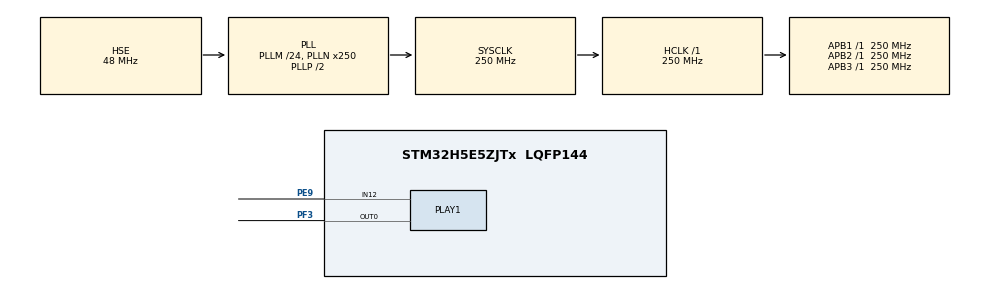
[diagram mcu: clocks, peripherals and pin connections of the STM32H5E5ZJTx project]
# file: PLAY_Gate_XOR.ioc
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CORTEX_M33_NS.userName=CORTEX_M33
Mcu.Family=STM32H5
Mcu.Name=STM32H5E5ZJTx
Mcu.Package=LQFP144
NVIC.PriorityGroup=NVIC_PRIORITYGROUP_4
PE9.GPIO_PuPd=GPIO_PULLDOWN
PE9.GPIO_Speed=GPIO_SPEED_FREQ_HIGH
PE9.Mode=PLAY1_IN12
PE9.Signal=PLAY1_IN12
PF3.GPIO_Speed=GPIO_SPEED_FREQ_HIGH
PF3.Mode=PLAY1_OUT0
PF3.Signal=PLAY1_OUT0
PH0-OSC_IN(PH0).Mode=HSE-External-Oscillator
PH0-OSC_IN(PH0).Signal=RCC_OSC_IN
PH1-OSC_OUT(PH1).Mode=HSE-External-Oscillator
PH1-OSC_OUT(PH1).Signal=RCC_OSC_OUT
PLAY1.Channel-PLAY1_IN12=PLAY_CHANNEL_12
PLAY1.InputPulseWidth12=100
PLAY1.InputSignal12=HAL_PLAY1_IN_IN12_MUX12
PLAY1.L0Input0=HAL_PLAY_LUT_INPUT_FILTER12
PLAY1.L0Input1=HAL_PLAY_LUT_INPUT_SWTRIG0
PLAY1.L0InputType0=InputSignal
PLAY1.L0LUT=0x6666
PLAY1.L1Input0=HAL_PLAY_LUT_INPUT_LUT11_OUT_REGISTERED
PLAY1.L1InputType0=OutputRegisteredSignal
PLAY1.L1InputType1=SWIN
PLAY1.LUT0InputUsage0=enable
PLAY1.LUT0InputUsage1=enable
PLAY1.LUT1InputUsage0=disable
PLAY1.LUT1InputUsage1=disable
PLAY1.OutputSignal0=HAL_PLAY_LUT0_OUT_DIRECT
ProjectManager.HeapSize=0x200
ProjectManager.StackSize=0x400
ProjectManager.TargetToolchain=EWARM V9.20
RCC.ADCFreq_Value=250000000
RCC.AHBFreq_Value=250000000
RCC.APB1Freq_Value=250000000
RCC.APB1TimFreq_Value=250000000
RCC.APB2Freq_Value=250000000
RCC.APB2TimFreq_Value=250000000
RCC.APB3Freq_Value=250000000
RCC.CSI_VALUE=4000000
RCC.CortexFreq_Value=250000000
RCC.EPOD_VALUE=48000000
RCC.HCLKFreq_Value=250000000
RCC.HSE_VALUE=48000000
RCC.HSI48_VALUE=48000000
RCC.HSI_VALUE=64000000
RCC.LSE_VALUE=32768
RCC.LSIRC_VALUE=32000
RCC.PLAY1CLockSelection=RCC_PLAY1CLKSOURCE_PLL2P
RCC.PLL2M=2
RCC.PLL2N=8
RCC.PLL2Source=RCC_PLL2_SOURCE_HSI
RCC.PLLM=24
RCC.PLLN=250
RCC.PLLSourceVirtual=RCC_PLL1_SOURCE_HSE
RCC.SYSCLKFreq_VALUE=250000000
RCC.SYSCLKSource=RCC_SYSCLKSOURCE_PLLCLK
RCC.USBFreq_Value=258000000
RCC.VCOOutputFreq_Value=500000000
VP_CORTEX_M33_NS_VS_Hclk.Mode=Hclk_Mode
VP_ICACHE_VS_ICACHE.Mode=DefaultMode
VP_PLAY1_VS_PLA.Mode=PLAY_Activate
VP_PWR_VS_LPOM.Mode=PowerOptimisation
VP_PWR_VS_SECSignals.Mode=Security/Privilege
board=custom

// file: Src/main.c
/* USER CODE BEGIN Header */
/**
  ******************************************************************************
  * @file           : main.c
  * @brief          : Main program body
  ******************************************************************************
  * @attention
  *
  * Copyright (c) 2025 STMicroelectronics.
  * All rights reserved.
  *
  * This software is licensed under terms that can be found in the LICENSE file
  * in the root directory of this software component.
  * If no LICENSE file comes with this software, it is provided AS-IS.
  *
  ******************************************************************************
  */
/* USER CODE END Header */
#include "main.h"

#define CONFIGURED_INPUT_NBR   1U
#define CONFIGURED_LUT_NBR     1U
#define CONFIGURED_OUTPUT_NBR  1U

HAL_PLAY_HandleTypeDef hplay1;

void SystemClock_Config(void);
static void MX_GPIO_Init(void);
static void MX_ICACHE_Init(void);
static void MX_PLAY1_Init(void);

int main(void)
{

  /* USER CODE BEGIN 1 */
  HAL_PLAY_EdgeTriggerConfTypeDef edge_trigger_config;

  /* USER CODE END 1 */

  /* MCU Configuration--------------------------------------------------------*/

  /* Reset of all peripherals, Initializes the Flash interface and the Systick. */
  HAL_Init();

  /* Configure the system clock */
  SystemClock_Config();

  /* Initialize all configured peripherals */
  MX_GPIO_Init();
  MX_ICACHE_Init();
  MX_PLAY1_Init();
  /* USER CODE BEGIN 2 */
  BSP_LED_Init(LED_RED);

  /* In this example, edge triggers are not used */
  edge_trigger_config.lut_out_falling_mask = 0U;
  edge_trigger_config.lut_out_rising_mask = 0U;

  /* Start PLAY module */
  if (HAL_PLAY_Start(&hplay1, &edge_trigger_config) != HAL_OK)
  {
    Error_Handler();
  }

  /* USER CODE END 2 */

  /* Infinite loop */
  /* USER CODE BEGIN WHILE */
  while (1)
  {
    /* Toggle the second input with a software trigger */
    if (HAL_PLAY_ToggleSWTrigger(&hplay1, HAL_PLAY_SWTRIG0, 100U) != HAL_OK)
    {
      Error_Handler();
    }

    HAL_Delay(1000);

    /* USER CODE END WHILE */

  }
}

void SystemClock_Config(void)
{
  RCC_OscInitTypeDef RCC_OscInitStruct = {0};
  RCC_ClkInitTypeDef RCC_ClkInitStruct = {0};

  /** Configure the main internal regulator output voltage
  */
  __HAL_PWR_VOLTAGESCALING_CONFIG(PWR_REGULATOR_VOLTAGE_SCALE0);

  while(!__HAL_PWR_GET_FLAG(PWR_FLAG_VOSRDY)) {}

  /** Initializes the RCC Oscillators according to the specified parameters
  * in the RCC_OscInitTypeDef structure.
  */
  RCC_OscInitStruct.OscillatorType = RCC_OSCILLATORTYPE_HSI|RCC_OSCILLATORTYPE_HSE;
  RCC_OscInitStruct.HSEState = RCC_HSE_ON;
  RCC_OscInitStruct.HSIState = RCC_HSI_ON;
  RCC_OscInitStruct.HSIDiv = RCC_HSI_DIV2;
  RCC_OscInitStruct.HSICalibrationValue = RCC_HSICALIBRATION_DEFAULT;
  RCC_OscInitStruct.PLL.PLLState = RCC_PLL_ON;
  RCC_OscInitStruct.PLL.PLLSource = RCC_PLL1_SOURCE_HSE;
  RCC_OscInitStruct.PLL.PLLM = 24;
  RCC_OscInitStruct.PLL.PLLN = 250;
  RCC_OscInitStruct.PLL.PLLP = 2;
  RCC_OscInitStruct.PLL.PLLQ = 2;
  RCC_OscInitStruct.PLL.PLLR = 2;
  RCC_OscInitStruct.PLL.PLLRGE = RCC_PLL1_VCIRANGE_1;
  RCC_OscInitStruct.PLL.PLLVCOSEL = RCC_PLL1_VCORANGE_WIDE;
  RCC_OscInitStruct.PLL.PLLFRACN = 0;
  if (HAL_RCC_OscConfig(&RCC_OscInitStruct) != HAL_OK)
  {
    Error_Handler();
  }

  /** Initializes the CPU, AHB and APB buses clocks
  */
  RCC_ClkInitStruct.ClockType = RCC_CLOCKTYPE_HCLK|RCC_CLOCKTYPE_SYSCLK
                              |RCC_CLOCKTYPE_PCLK1|RCC_CLOCKTYPE_PCLK2
                              |RCC_CLOCKTYPE_PCLK3;
  RCC_ClkInitStruct.SYSCLKSource = RCC_SYSCLKSOURCE_PLLCLK;
  RCC_ClkInitStruct.AHBCLKDivider = RCC_SYSCLK_DIV1;
  RCC_ClkInitStruct.APB1CLKDivider = RCC_HCLK_DIV1;
  RCC_ClkInitStruct.APB2CLKDivider = RCC_HCLK_DIV1;
  RCC_ClkInitStruct.APB3CLKDivider = RCC_HCLK_DIV1;

  if (HAL_RCC_ClockConfig(&RCC_ClkInitStruct, FLASH_LATENCY_5) != HAL_OK)
  {
    Error_Handler();
  }

  /** Configure the programming delay
  */
  __HAL_FLASH_SET_PROGRAM_DELAY(FLASH_PROGRAMMING_DELAY_2);
}

static void MX_ICACHE_Init(void)
{

  /** Enable instruction cache (default 2-ways set associative cache)
  */
  if (HAL_ICACHE_Enable() != HAL_OK)
  {
    Error_Handler();
  }

}

static void MX_PLAY1_Init(void)
{

  HAL_PLAY_IN_ConfTypeDef configINPUTs[CONFIGURED_INPUT_NBR];
  HAL_PLAY_LUT_ConfTypeDef configLUTs[CONFIGURED_LUT_NBR];
  HAL_PLAY_OUT_ConfTypeDef configOUTPUTs[CONFIGURED_OUTPUT_NBR];

  hplay1.instance = PLAY1;

  if (HAL_PLAY_Init(&hplay1) != HAL_OK)
  {
    Error_Handler();
  }

  /** Configure Input 12
  */
  configINPUTs[0].min_pulse_width = 100;
  configINPUTs[0].mode = HAL_PLAY_EDGE_DETECTION_BYPASSED;
  configINPUTs[0].source = HAL_PLAY1_IN_IN12_MUX12;
  if (HAL_PLAY_INPUT_SetConfig(&hplay1, configINPUTs, CONFIGURED_INPUT_NBR) != HAL_OK)
  {
    Error_Handler();
  }

  /** Configure the Logic Element 0
  */
  configLUTs[0].lut = HAL_PLAY_LUT0;
  configLUTs[0].truth_table = 0x6666;
  configLUTs[0].input_source[HAL_PLAY_LUT_INPUT0] = HAL_PLAY_LUT_INPUT_FILTER12;
  configLUTs[0].input_source[HAL_PLAY_LUT_INPUT1] = HAL_PLAY_LUT_INPUT_SWTRIG0;
  configLUTs[0].input_source[HAL_PLAY_LUT_INPUT2] = HAL_PLAY_LUT_INPUT_DEFAULT;
  configLUTs[0].input_source[HAL_PLAY_LUT_INPUT3] = HAL_PLAY_LUT_INPUT_DEFAULT;
  configLUTs[0].clk_gate_source = HAL_PLAY_LUT_CLK_GATE_OFF;
  if (HAL_PLAY_LUT_SetConfig(&hplay1, configLUTs, CONFIGURED_LUT_NBR) != HAL_OK)
  {
    Error_Handler();
  }

  /** Configure Output 0
  */
  configOUTPUTs[0].output_mux = HAL_PLAY_OUT0;
  configOUTPUTs[0].lut_output = HAL_PLAY_LUT0_OUT_DIRECT;
  if (HAL_PLAY_OUTPUT_SetConfig(&hplay1, configOUTPUTs, CONFIGURED_OUTPUT_NBR) != HAL_OK)
  {
    Error_Handler();
  }

  /** PLAY Privileged access configuration
  */
  HAL_PLAY_SetPrivAttr(&hplay1, HAL_PLAY_PRIV_ITEM_ALL, HAL_PLAY_NPRIV);

}

static void MX_GPIO_Init(void)
{

  /* GPIO Ports Clock Enable */
  __HAL_RCC_GPIOH_CLK_ENABLE();

}

void Error_Handler(void)
{
  /* USER CODE BEGIN Error_Handler_Debug */
  /* User can add his own implementation to report the HAL error return state */
  __disable_irq();
  while (1)
  {
    BSP_LED_Toggle(LED_RED);
    HAL_Delay(1000);
  }
  /* USER CODE END Error_Handler_Debug */
}
